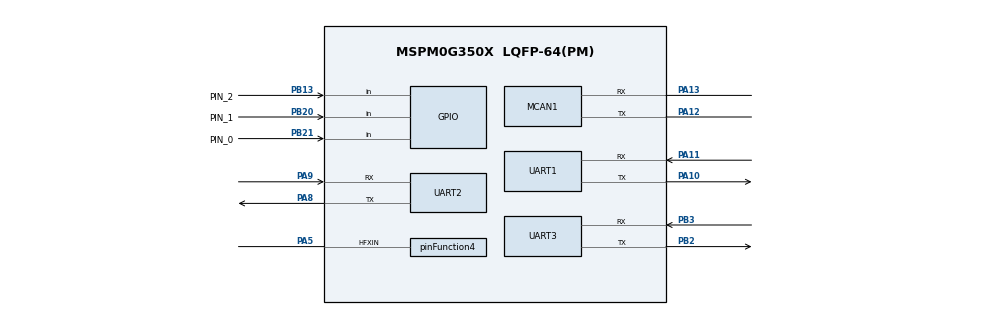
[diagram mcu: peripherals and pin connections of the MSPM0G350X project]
/**
 *
 * @cliArgs --device "MSPM0G350X" --part "Default" --package "LQFP-64(PM)" --product "mspm0_sdk@2.10.00.04"
 * @versions {"tool":"1.28.0+4696"}
 */

/**
 * Import the modules used in this configuration.
 */
const GPIO   = scripting.addModule("/ti/driverlib/GPIO", {}, false);
const GPIO1  = GPIO.addInstance();
const GPIO2  = GPIO.addInstance();
const GPIO3  = GPIO.addInstance();
const MCAN   = scripting.addModule("/ti/driverlib/MCAN", {}, false);
const MCAN1  = MCAN.addInstance();
const SYSCTL = scripting.addModule("/ti/driverlib/SYSCTL");
const UART   = scripting.addModule("/ti/driverlib/UART", {}, false);
const UART1  = UART.addInstance();
const UART2  = UART.addInstance();
const UART3  = UART.addInstance();

/**
 * Write custom configuration values to the imported modules.
 */
const gate7  = system.clockTree["MFCLKGATE"];
gate7.enable = true;

const mux4       = system.clockTree["EXHFMUX"];
mux4.inputSelect = "EXHFMUX_XTAL";

const pinFunction3     = system.clockTree["HFCLKEXT"];
pinFunction3.inputFreq = 40;

const pinFunction4                       = system.clockTree["HFXT"];
pinFunction4.enable                      = true;
pinFunction4.HFXTStartup                 = 10;
pinFunction4.HFCLKMonitor                = true;
pinFunction4.inputFreq                   = 40;
pinFunction4.peripheral.hfxInPin.$assign = "PA5";

GPIO1.$name                              = "KEY";
GPIO1.associatedPins[0].$name            = "PIN_0";
GPIO1.associatedPins[0].direction        = "INPUT";
GPIO1.associatedPins[0].internalResistor = "PULL_UP";
GPIO1.associatedPins[0].pin.$assign      = "PB21";

const Board = scripting.addModule("/ti/driverlib/Board", {}, false);

GPIO2.$name                              = "KEY1";
GPIO2.associatedPins[0].$name            = "PIN_1";
GPIO2.associatedPins[0].direction        = "INPUT";
GPIO2.associatedPins[0].internalResistor = "PULL_UP";
GPIO2.associatedPins[0].pin.$assign      = "PB20";

GPIO3.$name                              = "KEY2";
GPIO3.associatedPins[0].$name            = "PIN_2";
GPIO3.associatedPins[0].direction        = "INPUT";
GPIO3.associatedPins[0].internalResistor = "PULL_UP";
GPIO3.associatedPins[0].pin.$assign      = "PB13";

MCAN1.$name                    = "MCAN0";
MCAN1.wkupReqEnable            = true;
MCAN1.autoWkupEnable           = true;
MCAN1.emulationEnable          = true;
MCAN1.tdcEnable                = true;
MCAN1.additionalCoreConfig     = true;
MCAN1.rrfe                     = true;
MCAN1.rrfs                     = true;
MCAN1.anfe                     = "1";
MCAN1.anfs                     = "1";
MCAN1.txEventFIFOWaterMark     = 0;
MCAN1.overrideRetention        = true;
MCAN1.stdFiltType              = "01";
MCAN1.flesa                    = 0;
MCAN1.lse                      = 0;
MCAN1.desiredDataRate          = 2;
MCAN1.rxFIFO1waterMark         = 0;
MCAN1.rxFIFO0waterMark         = 0;
MCAN1.lss                      = 0;
MCAN1.rxFIFO0startAddr         = 0;
MCAN1.rxFIFO1startAddr         = 0;
MCAN1.rxBufStartAddr           = 0;
MCAN1.rxFIFO1size              = 0;
MCAN1.rxFIFO0size              = 0;
MCAN1.txStartAddr              = 0;
MCAN1.txBufNum                 = 1;
MCAN1.txEventFIFOStartAddr     = 0;
MCAN1.peripheral.$assign       = "CANFD0";
MCAN1.peripheral.rxPin.$assign = "PA13";
MCAN1.peripheral.txPin.$assign = "PA12";
MCAN1.txPinConfig.$name        = "ti_driverlib_gpio_GPIOPinGeneric6";
MCAN1.rxPinConfig.$name        = "ti_driverlib_gpio_GPIOPinGeneric7";

SYSCTL.CANCLKSource          = "HFCLK";
SYSCTL.useHFCLK_Manual       = true;
SYSCTL.HFCLKSource           = "HFXT";
SYSCTL.HFCLK_Freq            = 48000000;
SYSCTL.HFCLKMonitor          = true;
SYSCTL.forceDefaultClkConfig = true;
SYSCTL.clockTreeEn           = true;

UART1.$name                    = "UART_0";
UART1.enabledInterrupts        = ["RX"];
UART1.targetBaudRate           = 115200;
UART1.uartClkSrc               = "MFCLK";
UART1.peripheral.$assign       = "UART0";
UART1.peripheral.rxPin.$assign = "PA11";
UART1.peripheral.txPin.$assign = "PA10";
UART1.txPinConfig.$name        = "ti_driverlib_gpio_GPIOPinGeneric0";
UART1.rxPinConfig.$name        = "ti_driverlib_gpio_GPIOPinGeneric1";

UART2.$name                            = "UART_2";
UART2.targetBaudRate                   = 115200;
UART2.enabledInterrupts                = ["RX"];
UART2.peripheral.rxPin.$assign         = "PA9";
UART2.peripheral.txPin.$assign         = "PA8";
UART2.txPinConfig.direction            = scripting.forceWrite("OUTPUT");
UART2.txPinConfig.hideOutputInversion  = scripting.forceWrite(false);
UART2.txPinConfig.onlyInternalResistor = scripting.forceWrite(false);
UART2.txPinConfig.passedPeripheralType = scripting.forceWrite("Digital");
UART2.txPinConfig.$name                = "ti_driverlib_gpio_GPIOPinGeneric2";
UART2.rxPinConfig.hideOutputInversion  = scripting.forceWrite(false);
UART2.rxPinConfig.onlyInternalResistor = scripting.forceWrite(false);
UART2.rxPinConfig.passedPeripheralType = scripting.forceWrite("Digital");
UART2.rxPinConfig.$name                = "ti_driverlib_gpio_GPIOPinGeneric3";

UART3.$name                            = "UART_1";
UART3.targetBaudRate                   = 115200;
UART3.enabledInterrupts                = ["RX"];
UART3.peripheral.$assign               = "UART3";
UART3.peripheral.rxPin.$assign         = "PB3";
UART3.peripheral.txPin.$assign         = "PB2";
UART3.txPinConfig.direction            = scripting.forceWrite("OUTPUT");
UART3.txPinConfig.hideOutputInversion  = scripting.forceWrite(false);
UART3.txPinConfig.onlyInternalResistor = scripting.forceWrite(false);
UART3.txPinConfig.passedPeripheralType = scripting.forceWrite("Digital");
UART3.txPinConfig.$name                = "ti_driverlib_gpio_GPIOPinGeneric4";
UART3.rxPinConfig.hideOutputInversion  = scripting.forceWrite(false);
UART3.rxPinConfig.onlyInternalResistor = scripting.forceWrite(false);
UART3.rxPinConfig.passedPeripheralType = scripting.forceWrite("Digital");
UART3.rxPinConfig.$name                = "ti_driverlib_gpio_GPIOPinGeneric5";

/**
 * Pinmux solution for unlocked pins/peripherals. This ensures that minor changes to the automatic solver in a future
 * version of the tool will not impact the pinmux you originally saw.  These lines can be completely deleted in order to
 * re-solve from scratch.
 */
pinFunction4.peripheral.$suggestSolution           = "SYSCTL";
pinFunction4.peripheral.hfxOutPin.$suggestSolution = "PA6";
Board.peripheral.$suggestSolution                  = "DEBUGSS";
Board.peripheral.swclkPin.$suggestSolution         = "PA20";
Board.peripheral.swdioPin.$suggestSolution         = "PA19";
UART2.peripheral.$suggestSolution                  = "UART1";
